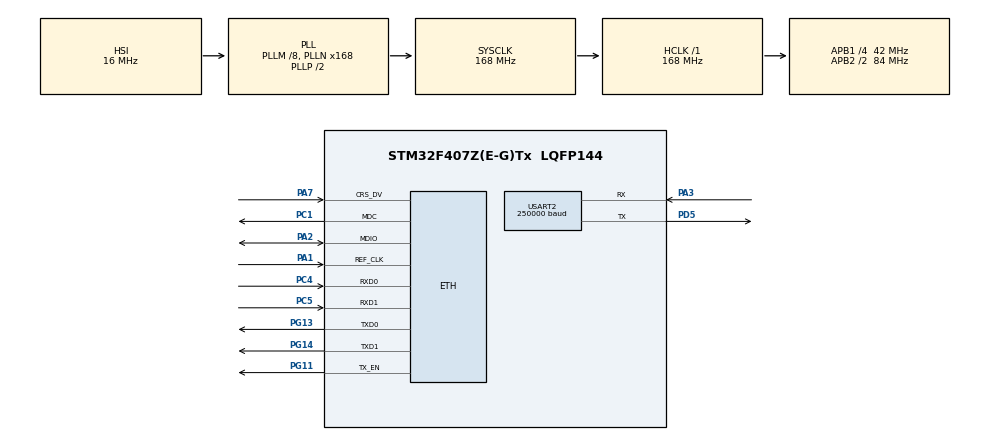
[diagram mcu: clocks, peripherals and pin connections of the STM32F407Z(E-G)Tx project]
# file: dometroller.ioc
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ETH.MACAddr=DE\:AD\:BE\:EF\:FE\:ED
ETH.MediaInterface=ETH_MEDIA_INTERFACE_RMII
ETH.PhyAddress=0
LWIP.CHECKSUM_BY_HARDWARE=1
LWIP.Version=v2.0.0_Cube
Mcu.Family=STM32F4
Mcu.Name=STM32F407Z(E-G)Tx
Mcu.Package=LQFP144
NVIC.PriorityGroup=NVIC_PRIORITYGROUP_4
NVIC.USART2_IRQn=true\:0\:0\:false\:true\:true\:1
PA1.Mode=RMII
PA1.Signal=ETH_REF_CLK
PA2.Mode=RMII
PA2.Signal=ETH_MDIO
PA3.Mode=Asynchronous
PA3.Signal=USART2_RX
PA7.Mode=RMII
PA7.Signal=ETH_CRS_DV
PC1.Mode=RMII
PC1.Signal=ETH_MDC
PC4.Mode=RMII
PC4.Signal=ETH_RXD0
PC5.Mode=RMII
PC5.Signal=ETH_RXD1
PD5.Mode=Asynchronous
PD5.Signal=USART2_TX
PG11.Mode=RMII
PG11.Signal=ETH_TX_EN
PG13.Mode=RMII
PG13.Signal=ETH_TXD0
PG14.Mode=RMII
PG14.Signal=ETH_TXD1
ProjectManager.HeapSize=0x200
ProjectManager.StackSize=0x400
ProjectManager.TargetToolchain=TrueSTUDIO
RCC.48MHZClocksFreq_Value=84000000
RCC.AHBFreq_Value=168000000
RCC.APB1CLKDivider=RCC_HCLK_DIV4
RCC.APB1Freq_Value=42000000
RCC.APB1TimFreq_Value=84000000
RCC.APB2CLKDivider=RCC_HCLK_DIV2
RCC.APB2Freq_Value=84000000
RCC.APB2TimFreq_Value=168000000
RCC.CortexFreq_Value=168000000
RCC.HCLKFreq_Value=168000000
RCC.HSE_VALUE=25000000
RCC.HSI_VALUE=16000000
RCC.LSE_VALUE=32768
RCC.PLLM=8
RCC.PLLN=168
RCC.SYSCLKFreq_VALUE=168000000
RCC.SYSCLKSource=RCC_SYSCLKSOURCE_PLLCLK
RCC.VCOOutputFreq_Value=336000000
USART2.BaudRate=250000
USART2.Mode=MODE_TX
USART2.StopBits=STOPBITS_2
USART2.VirtualMode=VM_ASYNC
VP_LWIP_VS_Enabled.Mode=Enabled
VP_TIM1_VS_ClockSourceITR.Mode=TriggerSource_ITR0
board=dometroller

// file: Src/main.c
/**
  ******************************************************************************
  * File Name          : main.c
  * Description        : Main program body
  ******************************************************************************
  * This notice applies to any and all portions of this file
  * that are not between comment pairs USER CODE BEGIN and
  * USER CODE END. Other portions of this file, whether
  * inserted by the user or by software development tools
  * are owned by their respective copyright owners.
  *
  * Copyright (c) 2017 STMicroelectronics International N.V.
  * All rights reserved.
  *
  * Redistribution and use in source and binary forms, with or without
  * modification, are permitted, provided that the following conditions are met:
  *
  * 1. Redistribution of source code must retain the above copyright notice,
  *    this list of conditions and the following disclaimer.
  * 2. Redistributions in binary form must reproduce the above copyright notice,
  *    this list of conditions and the following disclaimer in the documentation
  *    and/or other materials provided with the distribution.
  * 3. Neither the name of STMicroelectronics nor the names of other
  *    contributors to this software may be used to endorse or promote products
  *    derived from this software without specific written permission.
  * 4. This software, including modifications and/or derivative works of this
  *    software, must execute solely and exclusively on microcontroller or
  *    microprocessor devices manufactured by or for STMicroelectronics.
  * 5. Redistribution and use of this software other than as permitted under
  *    this license is void and will automatically terminate your rights under
  *    this license.
  *
  * THIS SOFTWARE IS PROVIDED BY STMICROELECTRONICS AND CONTRIBUTORS "AS IS"
  * AND ANY EXPRESS, IMPLIED OR STATUTORY WARRANTIES, INCLUDING, BUT NOT
  * LIMITED TO, THE IMPLIED WARRANTIES OF MERCHANTABILITY, FITNESS FOR A
  * PARTICULAR PURPOSE AND NON-INFRINGEMENT OF THIRD PARTY INTELLECTUAL PROPERTY
  * RIGHTS ARE DISCLAIMED TO THE FULLEST EXTENT PERMITTED BY LAW. IN NO EVENT
  * SHALL STMICROELECTRONICS OR CONTRIBUTORS BE LIABLE FOR ANY DIRECT, INDIRECT,
  * INCIDENTAL, SPECIAL, EXEMPLARY, OR CONSEQUENTIAL DAMAGES (INCLUDING, BUT NOT
  * LIMITED TO, PROCUREMENT OF SUBSTITUTE GOODS OR SERVICES; LOSS OF USE, DATA,
  * OR PROFITS; OR BUSINESS INTERRUPTION) HOWEVER CAUSED AND ON ANY THEORY OF
  * LIABILITY, WHETHER IN CONTRACT, STRICT LIABILITY, OR TORT (INCLUDING
  * NEGLIGENCE OR OTHERWISE) ARISING IN ANY WAY OUT OF THE USE OF THIS SOFTWARE,
  * EVEN IF ADVISED OF THE POSSIBILITY OF SUCH DAMAGE.
  *
  ******************************************************************************
  */
#include "main.h"
#include "stm32f4xx_hal.h"
#include "lwip.h"

/* USER CODE BEGIN Includes */
#include "config.h"
#include "udp_echoserver.h"
#include "visEffect.h"
#include "artnet/artnet.h"
/* USER CODE END Includes */

TIM_HandleTypeDef htim1;

UART_HandleTypeDef huart2;

/* USER CODE BEGIN PV */
/* Private variables ---------------------------------------------------------*/
__IO ITStatus UartReady = RESET;
/* USER CODE END PV */

void SystemClock_Config(void);
static void MX_GPIO_Init(void);
static void MX_TIM1_Init(void);
static void MX_USART2_UART_Init(void);
static void MX_NVIC_Init(void);

/* USER CODE BEGIN PFP */
/* Private function prototypes -----------------------------------------------*/

/* USER CODE END PFP */

int main(void)
{

  /* MCU Configuration----------------------------------------------------------*/

  /* Reset of all peripherals, Initializes the Flash interface and the Systick. */
  HAL_Init();

  /* Configure the system clock */
  SystemClock_Config();

  /* Initialize all configured peripherals */
  MX_GPIO_Init();
  MX_LWIP_Init();
  MX_TIM1_Init();
  MX_USART2_UART_Init();

  /* Initialize interrupts */
  MX_NVIC_Init();

  /* USER CODE BEGIN 2 */
  /* udp echo server Init */
//  udp_echoserver_init();
  artnetInit();
  visInit(huart2);
  /* USER CODE END 2 */

  /* Infinite loop */
  while (1)
  {

  /* USER CODE BEGIN 3 */
	MX_LWIP_Process();
    visHandle();
//    if((sendDMX == 1) && (UartReady == SET)){
//    if(sendDMX == 1){
//    	sendDMXFrame();
//    	sendDMX = 0;
//    }
//	if(HAL_UART_GetState(&huart2) == HAL_UART_STATE_READY){
//		Delay(3000);
//		sendDMXFrame();
//		if(frameBuffer[16][3] >= 255){
//			frameBuffer[16][3] = 0;
//		}
//		else{
//			frameBuffer[16][3] = frameBuffer[16][3] + 1;
//		}
//	}

  }
  /* USER CODE END 3 */

}

/** System Clock Configuration
*/
void SystemClock_Config(void)
{

  RCC_OscInitTypeDef RCC_OscInitStruct;
  RCC_ClkInitTypeDef RCC_ClkInitStruct;

    /**Configure the main internal regulator output voltage
    */
  __HAL_RCC_PWR_CLK_ENABLE();

  __HAL_PWR_VOLTAGESCALING_CONFIG(PWR_REGULATOR_VOLTAGE_SCALE1);

    /**Initializes the CPU, AHB and APB busses clocks
    */
  RCC_OscInitStruct.OscillatorType = RCC_OSCILLATORTYPE_HSI;
  RCC_OscInitStruct.HSIState = RCC_HSI_ON;
  RCC_OscInitStruct.HSICalibrationValue = 16;
  RCC_OscInitStruct.PLL.PLLState = RCC_PLL_ON;
  RCC_OscInitStruct.PLL.PLLSource = RCC_PLLSOURCE_HSI;
  RCC_OscInitStruct.PLL.PLLM = 8;
  RCC_OscInitStruct.PLL.PLLN = 168;
  RCC_OscInitStruct.PLL.PLLP = RCC_PLLP_DIV2;
  RCC_OscInitStruct.PLL.PLLQ = 4;
  if (HAL_RCC_OscConfig(&RCC_OscInitStruct) != HAL_OK)
  {
    _Error_Handler(__FILE__, __LINE__);
  }

    /**Initializes the CPU, AHB and APB busses clocks
    */
  RCC_ClkInitStruct.ClockType = RCC_CLOCKTYPE_HCLK|RCC_CLOCKTYPE_SYSCLK
                              |RCC_CLOCKTYPE_PCLK1|RCC_CLOCKTYPE_PCLK2;
  RCC_ClkInitStruct.SYSCLKSource = RCC_SYSCLKSOURCE_PLLCLK;
  RCC_ClkInitStruct.AHBCLKDivider = RCC_SYSCLK_DIV1;
  RCC_ClkInitStruct.APB1CLKDivider = RCC_HCLK_DIV4;
  RCC_ClkInitStruct.APB2CLKDivider = RCC_HCLK_DIV2;

  if (HAL_RCC_ClockConfig(&RCC_ClkInitStruct, FLASH_LATENCY_5) != HAL_OK)
  {
    _Error_Handler(__FILE__, __LINE__);
  }

    /**Configure the Systick interrupt time
    */
  HAL_SYSTICK_Config(HAL_RCC_GetHCLKFreq()/1000);

    /**Configure the Systick
    */
  HAL_SYSTICK_CLKSourceConfig(SYSTICK_CLKSOURCE_HCLK);

  /* SysTick_IRQn interrupt configuration */
  HAL_NVIC_SetPriority(SysTick_IRQn, 0, 0);
}

/** NVIC Configuration
*/
static void MX_NVIC_Init(void)
{
  /* USART2_IRQn interrupt configuration */
  HAL_NVIC_SetPriority(USART2_IRQn, 0, 0);
  HAL_NVIC_EnableIRQ(USART2_IRQn);
}

/* TIM1 init function */
static void MX_TIM1_Init(void)
{

  TIM_SlaveConfigTypeDef sSlaveConfig;
  TIM_MasterConfigTypeDef sMasterConfig;

  htim1.Instance = TIM1;
  htim1.Init.Prescaler = 0;
  htim1.Init.CounterMode = TIM_COUNTERMODE_UP;
  htim1.Init.Period = 0;
  htim1.Init.ClockDivision = TIM_CLOCKDIVISION_DIV1;
  htim1.Init.RepetitionCounter = 0;
  if (HAL_TIM_Base_Init(&htim1) != HAL_OK)
  {
    _Error_Handler(__FILE__, __LINE__);
  }

  sSlaveConfig.SlaveMode = TIM_SLAVEMODE_DISABLE;
  sSlaveConfig.InputTrigger = TIM_TS_ITR0;
  if (HAL_TIM_SlaveConfigSynchronization(&htim1, &sSlaveConfig) != HAL_OK)
  {
    _Error_Handler(__FILE__, __LINE__);
  }

  sMasterConfig.MasterOutputTrigger = TIM_TRGO_RESET;
  sMasterConfig.MasterSlaveMode = TIM_MASTERSLAVEMODE_DISABLE;
  if (HAL_TIMEx_MasterConfigSynchronization(&htim1, &sMasterConfig) != HAL_OK)
  {
    _Error_Handler(__FILE__, __LINE__);
  }

}

/* USART2 init function */
static void MX_USART2_UART_Init(void)
{

  huart2.Instance = USART2;
  huart2.Init.BaudRate = 250000;
  huart2.Init.WordLength = UART_WORDLENGTH_8B;
  huart2.Init.StopBits = UART_STOPBITS_2;
  huart2.Init.Parity = UART_PARITY_NONE;
  huart2.Init.Mode = UART_MODE_TX;
  huart2.Init.HwFlowCtl = UART_HWCONTROL_NONE;
  huart2.Init.OverSampling = UART_OVERSAMPLING_16;
  if (HAL_UART_Init(&huart2) != HAL_OK)
  {
    _Error_Handler(__FILE__, __LINE__);
  }

}

/** Pinout Configuration
*/
static void MX_GPIO_Init(void)
{

  /* GPIO Ports Clock Enable */
  __HAL_RCC_GPIOC_CLK_ENABLE();
  __HAL_RCC_GPIOA_CLK_ENABLE();
  __HAL_RCC_GPIOD_CLK_ENABLE();
  __HAL_RCC_GPIOG_CLK_ENABLE();

}

/* USER CODE BEGIN 4 */
//void sendDMXFrame(void){
//	huart2.Init.BaudRate = 125000;
//	HAL_UART_Init(&huart2);
//	HAL_UART_Transmit(&huart2, (uint8_t*)0, 1, 1000);
//	huart2.Init.BaudRate = 250000;
//	HAL_UART_Init(&huart2);
//	HAL_UART_Transmit_IT(&huart2, frameBuffer[16], 513);
//}

/**
  * @brief  Delay Function.
  * @param  nCount:specifies the Delay time length.
  * @retval None
  */
void Delay(__IO uint32_t nCount)
{
  while(nCount--)
  {
  }
}

void HAL_UART_TxCpltCallback(UART_HandleTypeDef *UartHandle)
{
  /* Set transmission flag: transfer complete */
  UartReady = SET;
}
/* USER CODE END 4 */

void _Error_Handler(char * file, int line)
{
  while(1)
  {
  }
}

/************************ (C) COPYRIGHT STMicroelectronics *****END OF FILE****/
